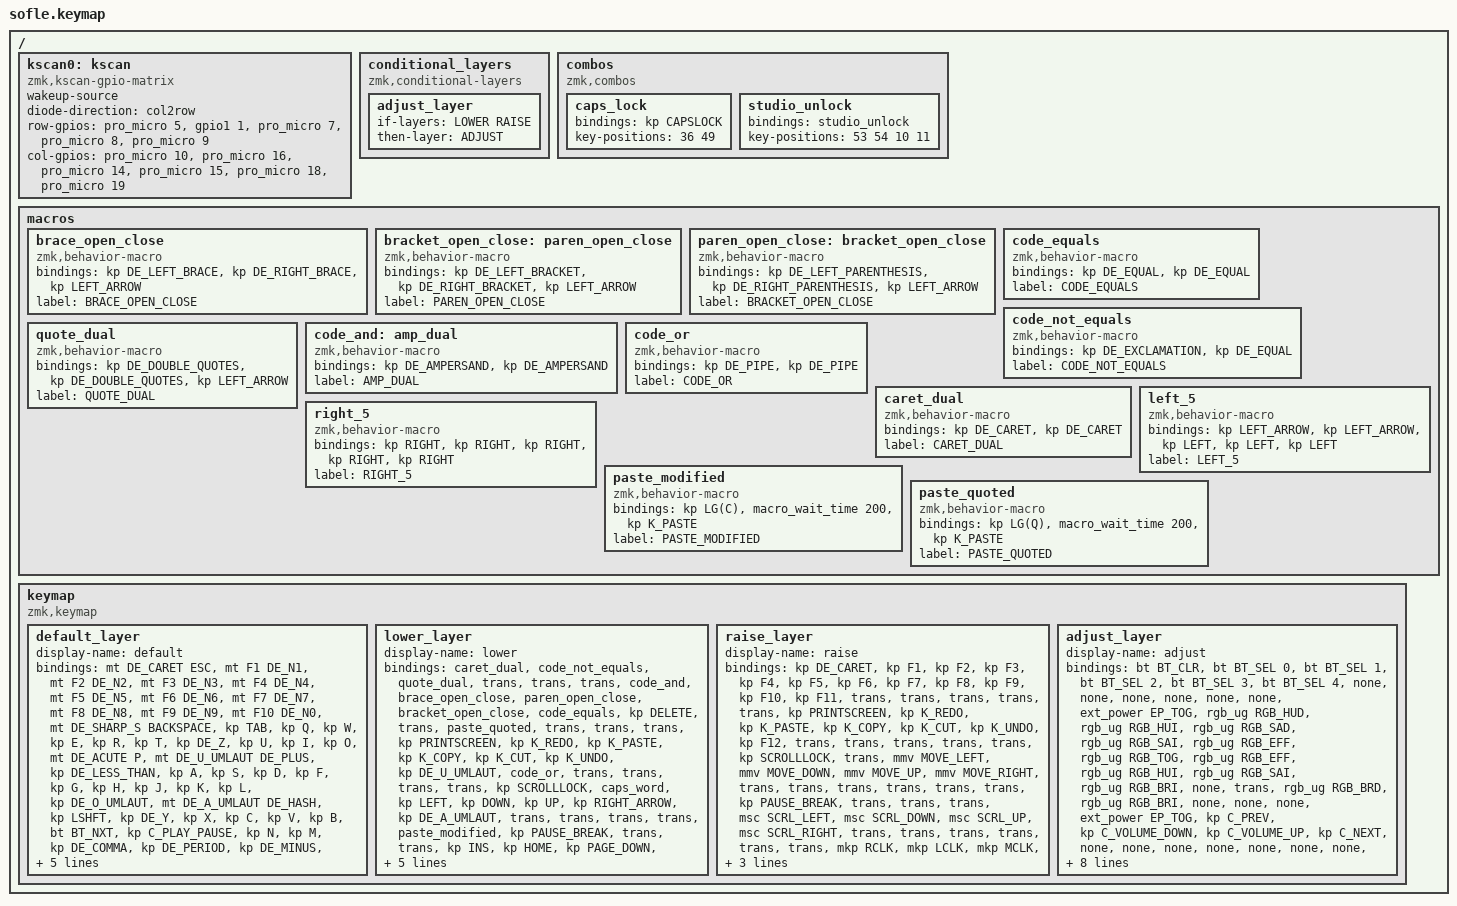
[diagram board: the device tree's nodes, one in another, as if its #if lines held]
/*
 * Copyright (c) 2020 The ZMK Contributors
 *
 * SPDX-License-Identifier: MIT
 */

#include <behaviors.dtsi>
#include <dt-bindings/zmk/bt.h>
#include <dt-bindings/zmk/ext_power.h>
#include <dt-bindings/zmk/keys.h>
#include <dt-bindings/zmk/outputs.h>
#include <dt-bindings/zmk/pointing.h>
#include <dt-bindings/zmk/rgb.h>

// [RA] https://github.com/nickcoutsos/keymap-editor/wiki/Keycodes-for-other-locales

#include "keys_de.h"

#define BASE 0
#define LOWER 1
#define RAISE 2
#define ADJUST 3

// https://zmk.dev/docs/features/low-power-states#wakeup-sources
// AI mode sez:

&kscan0 { wakeup-source; };

/ {
#if defined(SHIELD_SOFLE_RIGHT)

    kscan0: kscan {
        compatible = "zmk,kscan-gpio-matrix";
        wakeup-source;
        diode-direction = "col2row";
        row-gpios =
            <&pro_micro 5 (GPIO_ACTIVE_HIGH | GPIO_PULL_DOWN)>,
            // [RA] override blown "&pro_micro 6" aka 100 aka D6 P1.00 pin with 101 aka P1.01.
            // https://docs.splitkb.com/product-guides/nice-nano/schematics-and-pinout
            <&gpio1 1 (GPIO_ACTIVE_HIGH | GPIO_PULL_DOWN)>,
            <&pro_micro 7 (GPIO_ACTIVE_HIGH | GPIO_PULL_DOWN)>,
            <&pro_micro 8 (GPIO_ACTIVE_HIGH | GPIO_PULL_DOWN)>,
            <&pro_micro 9 (GPIO_ACTIVE_HIGH | GPIO_PULL_DOWN)>;

        col-gpios =
            <&pro_micro 10 GPIO_ACTIVE_HIGH>,
            <&pro_micro 16 GPIO_ACTIVE_HIGH>,
            <&pro_micro 14 GPIO_ACTIVE_HIGH>,
            <&pro_micro 15 GPIO_ACTIVE_HIGH>,
            <&pro_micro 18 GPIO_ACTIVE_HIGH>,
            <&pro_micro 19 GPIO_ACTIVE_HIGH>;
    };

#endif

    conditional_layers {
        compatible = "zmk,conditional-layers";

        adjust_layer {
            if-layers = <LOWER RAISE>;
            then-layer = <ADJUST>;
        };
    };

    combos {
        compatible = "zmk,combos";

        caps_lock {
            bindings = <&kp CAPSLOCK>;
            key-positions = <36 49>;
        };

        studio_unlock {
            bindings = <&studio_unlock>;
            key-positions = <53 54 10 11>;
        };
    };

    macros {
        brace_open_close: brace_open_close {
            compatible = "zmk,behavior-macro";
            #binding-cells = <0>;
            bindings = <&kp DE_LEFT_BRACE &kp DE_RIGHT_BRACE &kp LEFT_ARROW>;
            label = "BRACE_OPEN_CLOSE";
        };

        bracket_open_close: paren_open_close {
            compatible = "zmk,behavior-macro";
            #binding-cells = <0>;
            bindings = <&kp DE_LEFT_BRACKET &kp DE_RIGHT_BRACKET &kp LEFT_ARROW>;
            label = "PAREN_OPEN_CLOSE";
        };

        paren_open_close: bracket_open_close {
            compatible = "zmk,behavior-macro";
            #binding-cells = <0>;
            bindings = <&kp DE_LEFT_PARENTHESIS &kp DE_RIGHT_PARENTHESIS &kp LEFT_ARROW>;
            label = "BRACKET_OPEN_CLOSE";
        };

        code_equals: code_equals {
            compatible = "zmk,behavior-macro";
            #binding-cells = <0>;
            bindings = <&kp DE_EQUAL &kp DE_EQUAL>;
            label = "CODE_EQUALS";
        };

        code_not_equals: code_not_equals {
            compatible = "zmk,behavior-macro";
            #binding-cells = <0>;
            bindings = <&kp DE_EXCLAMATION &kp DE_EQUAL>;
            label = "CODE_NOT_EQUALS";
        };

        quote_dual: quote_dual {
            compatible = "zmk,behavior-macro";
            #binding-cells = <0>;
            bindings = <&kp DE_DOUBLE_QUOTES &kp DE_DOUBLE_QUOTES &kp LEFT_ARROW>;
            label = "QUOTE_DUAL";
        };

        code_and: amp_dual {
            compatible = "zmk,behavior-macro";
            #binding-cells = <0>;
            bindings = <&kp DE_AMPERSAND &kp DE_AMPERSAND>;
            label = "AMP_DUAL";
        };

        code_or: code_or {
            compatible = "zmk,behavior-macro";
            #binding-cells = <0>;
            bindings = <&kp DE_PIPE &kp DE_PIPE>;
            label = "CODE_OR";
        };

        caret_dual: caret_dual {
            compatible = "zmk,behavior-macro";
            #binding-cells = <0>;
            bindings = <&kp DE_CARET &kp DE_CARET>;
            label = "CARET_DUAL";
        };

        left_5: left_5 {
            compatible = "zmk,behavior-macro";
            #binding-cells = <0>;
            bindings = <&kp LEFT_ARROW &kp LEFT_ARROW &kp LEFT &kp LEFT &kp LEFT>;
            label = "LEFT_5";
        };

        right_5: right_5 {
            compatible = "zmk,behavior-macro";
            #binding-cells = <0>;
            bindings = <&kp RIGHT &kp RIGHT &kp RIGHT &kp RIGHT &kp RIGHT>;
            label = "RIGHT_5";
        };

        paste_modified: paste_modified {
            compatible = "zmk,behavior-macro";
            #binding-cells = <0>;
            bindings = <&kp LG(C)>, <&macro_wait_time 200>, <&kp K_PASTE>;

            label = "PASTE_MODIFIED";
        };

        paste_quoted: paste_quoted {
            compatible = "zmk,behavior-macro";
            #binding-cells = <0>;
            bindings = <&kp LG(Q)>, <&macro_wait_time 200>, <&kp K_PASTE>;

            label = "PASTE_QUOTED";
        };
    };

    keymap {
        compatible = "zmk,keymap";

        default_layer {
            display-name = "default";

            // ------------------------------------------------------------------------------------------------------------
            // |   `   |  1  |  2  |  3   |  4   |  5   |                   |  6   |  7    |  8    |  9   |   0   |       |
            // |  ESC  |  Q  |  W  |  E   |  R   |  T   |                   |  Y   |  U    |  I    |  O   |   P   | BKSPC |
            // |  TAB  |  A  |  S  |  D   |  F   |  G   |                   |  H   |  J    |  K    |  L   |   ;   |   '   |
            // | SHIFT |  Z  |  X  |  C   |  V   |  B   |  MUTE  |  |       |  N   |  M    |  ,    |  .   |   /   | SHIFT |
            //               | GUI | ALT  | CTRL | LOWER|  ENTER |  | SPACE | RAISE| CTRL  | ALT   | GUI  |

            bindings = <
&mt DE_CARET ESC  &mt F1 DE_N1  &mt F2 DE_N2  &mt F3 DE_N3  &mt F4 DE_N4  &mt F5 DE_N5                                     &mt F6 DE_N6  &mt F7 DE_N7  &mt F8 DE_N8  &mt F9 DE_N9   &mt F10 DE_N0    &mt DE_SHARP_S BACKSPACE
&kp TAB           &kp Q         &kp W         &kp E         &kp R         &kp T                                            &kp DE_Z      &kp U         &kp I         &kp O          &mt DE_ACUTE P   &mt DE_U_UMLAUT DE_PLUS
&kp DE_LESS_THAN  &kp A         &kp S         &kp D         &kp F         &kp G                                            &kp H         &kp J         &kp K         &kp L          &kp DE_O_UMLAUT  &mt DE_A_UMLAUT DE_HASH
&kp LSHFT         &kp DE_Y      &kp X         &kp C         &kp V         &kp B            &bt BT_NXT    &kp C_PLAY_PAUSE  &kp N         &kp M         &kp DE_COMMA  &kp DE_PERIOD  &kp DE_MINUS     &kp RSHFT
                                &kp LCTRL     &kp LGUI      &kp LALT      &lt 1 BACKSPACE  &mo 2         &kp RET           &kp SPACE     &kp RALT      &kp C_MENU    &kp RCTRL
            >;

            sensor-bindings =
                <&inc_dec_kp PAGE_UP PAGE_DOWN>,
                <&inc_dec_kp (LS(LC(RIGHT))) LS(LC(LEFT_ARROW))>;
        };

        lower_layer {
            display-name = "lower";

            // TODO: Some binds are waiting for shifted keycode support.
            // ------------------------------------------------------------------------------------------------------------
            // |       |  F1 |  F2 |  F3  |  F4  |  F5  |                   |  F6  |  F7   |  F8   |  F9  |  F10  |  F11  |
            // |   `   |  1  |  2  |  3   |  4   |  5   |                   |  6   |  7    |  8    |  9   |   0   |  F12  |
            // |       |  !  |  @  |  #   |  $   |  %   |                   |  ^   |  &    |  *    |  (   |   )   |   |   |
            // |       |  =  |  -  |  +   |  {   |  }   |        |  |       |  [   |  ]    |  ;    |  :   |   \   |       |
            //               |     |      |      |      |        |  |       |      |       |       |      |

            bindings = <
&caret_dual  &code_not_equals  &quote_dual  &trans  &trans           &trans                             &code_and      &brace_open_close  &paren_open_close  &bracket_open_close  &code_equals     &kp DELETE
&trans       &paste_quoted     &trans       &trans  &trans           &kp PRINTSCREEN                    &kp K_REDO     &kp K_PASTE        &kp K_COPY         &kp K_CUT            &kp K_UNDO       &kp DE_U_UMLAUT
&code_or     &trans            &trans       &trans  &trans           &kp SCROLLLOCK                     &caps_word     &kp LEFT           &kp DOWN           &kp UP               &kp RIGHT_ARROW  &kp DE_A_UMLAUT
&trans       &trans            &trans       &trans  &paste_modified  &kp PAUSE_BREAK  &trans    &trans  &kp INS        &kp HOME           &kp PAGE_DOWN      &kp PAGE_UP          &kp END          &trans
                               &trans       &trans  &trans           &trans           &trans    &trans  &kp BACKSPACE  &kp DELETE         &trans             &trans
            >;

            sensor-bindings =
                <&inc_dec_kp PAGE_UP PAGE_DOWN>,
                <&inc_dec_kp (LS(RIGHT)) LS(LEFT_ARROW)>;
        };

        raise_layer {
            display-name = "raise";

            // ------------------------------------------------------------------------------------------------------------
            // | BTCLR | BT1  | BT2  |  BT3  |  BT4  |  BT5 |                |      |      |       |      |       |       |
            // |       | INS  | PSCR | GUI   |       |      |                | PGUP |      |   ^   |      |       |       |
            // |       | ALT  | CTRL | SHIFT |       | CAPS |                | PGDN |   <- |   v   |  ->  |  DEL  | BKSPC |
            // |       | UNDO | CUT  | COPY  | PASTE |      |      |  |      |      |      |       |      |       |       |
            //                |      |       |       |      |      |  |      |      |      |       |      |

            bindings = <
&kp DE_CARET  &kp F1  &kp F2  &kp F3  &kp F4  &kp F5                                &kp F6      &kp F7          &kp F8          &kp F9        &kp F10          &kp F11
&trans        &trans  &trans  &trans  &trans  &kp PRINTSCREEN                       &kp K_REDO  &kp K_PASTE     &kp K_COPY      &kp K_CUT     &kp K_UNDO       &kp F12
&trans        &trans  &trans  &trans  &trans  &kp SCROLLLOCK                        &trans      &mmv MOVE_LEFT  &mmv MOVE_DOWN  &mmv MOVE_UP  &mmv MOVE_RIGHT  &trans
&trans        &trans  &trans  &trans  &trans  &kp PAUSE_BREAK  &trans    &trans     &trans      &msc SCRL_LEFT  &msc SCRL_DOWN  &msc SCRL_UP  &msc SCRL_RIGHT  &trans
                      &trans  &trans  &trans  &trans           &trans    &mkp RCLK  &mkp LCLK   &mkp MCLK       &trans          &trans
            >;

            sensor-bindings =
                <&inc_dec_kp C_VOL_UP C_VOL_DN>,
                <&inc_dec_kp (LC(RIGHT)) LC(LEFT_ARROW)>;
        };

        adjust_layer {
            // ----------------------------------------------------------------------------------------------------------------------------
            // | BTCLR  |  BT1    |  BT2    |   BT3   |   BT4   |   BT5   |                  |      |      |       |      |       |       |
            // | EXTPWR | RGB_HUD | RGB_HUI | RGB_SAD | RGB_SAI | RGB_EFF |                  |      |      |       |      |       |       |
            // |        | RGB_BRD | RGB_BRI |         |         |         |                  |      |      |       |      |       |       |
            // |        |         |         |         |         |         | RGB_TOG | |      |      |      |       |      |       |       |
            //                    |         |         |         |         |         | |      |      |      |       |      |

            display-name = "adjust";
            bindings = <
&bt BT_CLR         &bt BT_SEL 0     &bt BT_SEL 1     &bt BT_SEL 2     &bt BT_SEL 3     &bt BT_SEL 4                                    &none              &none            &none              &none            &none            &none
&ext_power EP_TOG  &rgb_ug RGB_HUD  &rgb_ug RGB_HUI  &rgb_ug RGB_SAD  &rgb_ug RGB_SAI  &rgb_ug RGB_EFF                                 &rgb_ug RGB_TOG    &rgb_ug RGB_EFF  &rgb_ug RGB_HUI    &rgb_ug RGB_SAI  &rgb_ug RGB_BRI  &none
&trans             &rgb_ug RGB_BRD  &rgb_ug RGB_BRI  &none            &none            &none                                           &ext_power EP_TOG  &kp C_PREV       &kp C_VOLUME_DOWN  &kp C_VOLUME_UP  &kp C_NEXT       &none
&none              &none            &none            &none            &none            &none            &rgb_ug RGB_TOG    &trans      &out OUT_TOG       &bt BT_SEL 0     &bt BT_SEL 1       &bt BT_SEL 2     &bt BT_SEL 3     &bt BT_SEL 4
                                    &none            &none            &none            &none            &none              &kp C_STOP  &kp C_PLAY_PAUSE   &kp C_MUTE       &none              &none
            >;

            sensor-bindings =
                <&inc_dec_kp C_FAST_FORWARD C_REWIND>,
                <&inc_dec_kp C_VOLUME_UP C_VOLUME_DOWN>;
        };
    };
};

#if defined(SHIELD_SOFLE_RIGHT)

    &kscan0 {
        compatible = "zmk,kscan-gpio-matrix";
        wakeup-source;
        diode-direction = "col2row";
        row-gpios =
            <&pro_micro 5 (GPIO_ACTIVE_HIGH | GPIO_PULL_DOWN)>,
            // [RA] override blown "&pro_micro 6" aka 100 aka D6 P1.00 pin with 101 aka P1.01.
            // https://docs.splitkb.com/product-guides/nice-nano/schematics-and-pinout
            <&gpio1 1 (GPIO_ACTIVE_HIGH | GPIO_PULL_DOWN)>,
            <&pro_micro 7 (GPIO_ACTIVE_HIGH | GPIO_PULL_DOWN)>,
            <&pro_micro 8 (GPIO_ACTIVE_HIGH | GPIO_PULL_DOWN)>,
            <&pro_micro 9 (GPIO_ACTIVE_HIGH | GPIO_PULL_DOWN)>;

        col-gpios =
            <&pro_micro 10 GPIO_ACTIVE_HIGH>,
            <&pro_micro 16 GPIO_ACTIVE_HIGH>,
            <&pro_micro 14 GPIO_ACTIVE_HIGH>,
            <&pro_micro 15 GPIO_ACTIVE_HIGH>,
            <&pro_micro 18 GPIO_ACTIVE_HIGH>,
            <&pro_micro 19 GPIO_ACTIVE_HIGH>;
    };

#endif

